# PRU_ICSS_0_INTC_local register map
Vendor: Texas Instruments
Peripheral module from a debugger description file (folder 66AK2G0x_66AK2G1x).
Registers are 32-bit, access per field, reset values left out (the file's numbers can be read two ways) unless marked. A register's access mark holds for its fields unless they carry their own. Offsets are as the file gives them; lines under a group give offsets from that group; [hi:lo] are bit positions; {n}, {i} and the like mark numbered series; 'fields as' and 'values as' point back to an identical list; <NAME> marks a mode.

## PRU_ICSS_0_INTC
0x00 PRUSS_INTC_REVID ro
  [31:0] REVISION — IP Revision
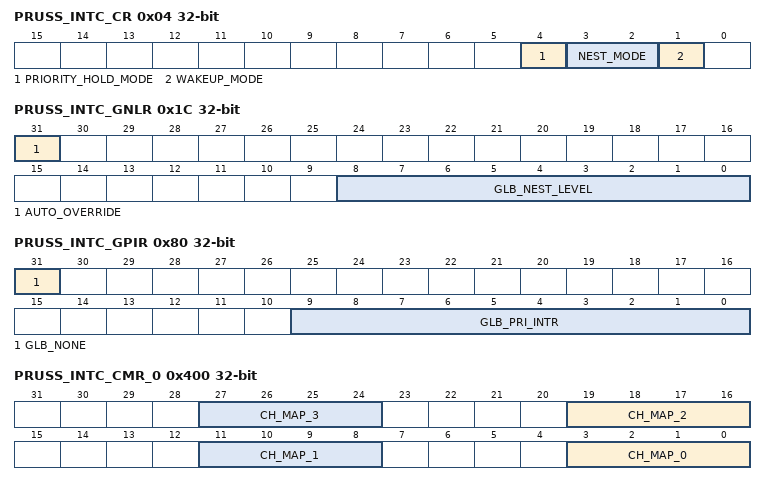
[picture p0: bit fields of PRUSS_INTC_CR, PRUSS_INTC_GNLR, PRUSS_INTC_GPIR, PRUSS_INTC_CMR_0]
0x04 PRUSS_INTC_CR
  [4] PRIORITY_HOLD_MODE rw — Reserved
  [3:2] NEST_MODE rw — The nesting mode.
  [1] WAKEUP_MODE rw — Reserved
0x10 PRUSS_INTC_GER
  [0] ENABLE_HINT_ANY rw — The current global enable value when read. Writes set the global enable.
0x1C PRUSS_INTC_GNLR
  [31] AUTO_OVERRIDE wo — Always read as 0. Writes of 1 override the automatic nesting and set the nesting_level to the written data.
  [8:0] GLB_NEST_LEVEL rw — The current global nesting level (highest channel that is nested). Writes set the nesting level. In auto nesting mode this value is updated internally unless the auto_override bit is set.
0x20 PRUSS_INTC_SISR
  [9:0] STATUS_SET_INDEX wo — Writes set the status of the interrupt given in the index value. Reads return 0.
0x24 PRUSS_INTC_SICR
  [9:0] STATUS_CLR_INDEX wo — Writes clear the status of the interrupt given in the index value. Reads return 0.
0x28 PRUSS_INTC_EISR
  [9:0] ENABLE_SET_INDEX wo — Writes set the enable of the interrupt given in the index value. Reads return 0.
0x2C PRUSS_INTC_EICR
  [9:0] ENABLE_CLR_INDEX wo — Writes clear the enable of the interrupt given in the index value. Reads return 0.
0x34 PRUSS_INTC_HIEISR
  [9:0] HINT_ENABLE_SET_INDEX rw — Writes set the enable of the host interrupt given in the index value. Reads return 0.
0x38 PRUSS_INTC_HIDISR
  [9:0] HINT_ENABLE_CLR_INDEX rw — Writes clear the enable of the host interrupt given in the index value. Reads return 0.
0x80 PRUSS_INTC_GPIR ro
  [31] GLB_NONE — No Interrupt is pending. Can be used by host to test for a negative value to see if no interrupts are pending.
  [9:0] GLB_PRI_INTR — The currently highest priority interrupt index pending across all the host interrupts.
0x200 PRUSS_INTC_SRSR0 rw
  [31:0] RAW_STATUS_31_0 — System interrupt raw status and setting of the system interrupts 0 to 31. Reads return the raw status. Write a 1 in a bit position to set the status of the system interrupt. Writing a 0 has no effect.
0x204 PRUSS_INTC_SRSR1 rw
  [31:0] RAW_STATUS_63_32 — System interrupt raw status and setting of the system interrupts 32 to 63. Reads return the raw status. Write a 1 in a bit position to set the status of the system interrupt. Writing a 0 has no effect.
0x280 PRUSS_INTC_SECR0 rw
  [31:0] ENA_STATUS_31_0 — System interrupt enabled status and clearing of the system interrupts 0 to 31. Reads return the enabled status (before enabling with the Enable Registers). Write a 1 in a bit position to clear the status of the system interrupt. Writing a 0 has no effect.
0x284 PRUSS_INTC_SECR1 rw
  [31:0] ENA_STATUS_63_32 — System interrupt enabled status and clearing of the system interrupts 32 to 63. Reads return the enabled status (before enabling with the Enable Registers). Write a 1 in a bit position to clear the status of the system interrupt. Writing a 0 has no effect.
0x300 PRUSS_INTC_ESR0 rw
  [31:0] ENABLE_SET_31_0 — System interrupt enables system interrupts 0 to 31. Read returns the enable value (0 = disabled, 1 = enabled). Write a 1 in a bit position to set that enable. Writing a 0 has no effect.
0x304 PRUSS_INTC_ERS1 rw
  [31:0] ENABLE_SET_63_32 — System interrupt enables system interrupts 32 to 63. Read returns the enable value (0 = disabled, 1 = enabled). Write a 1 in a bit position to set that enable. Writing a 0 has no effect.
0x380 PRUSS_INTC_ECR0 wo
  [31:0] ENABLE_CLR_31_0 — System interrupt enables system interrupts 0 to 31. Write a 1 in a bit position to clear that enable. Writing a 0 has no effect.
0x384 PRUSS_INTC_ECR1 wo
  [31:0] ENABLE_CLR_63_32 — System interrupt enables system interrupts 32 to 63. Write a 1 in a bit position to clear that enable. Writing a 0 has no effect.
0x400 PRUSS_INTC_CMR_0
  [8n+3:8n] CH_MAP_{n} rw (n=0..3) — Sets the channel for the system interrupt {n}
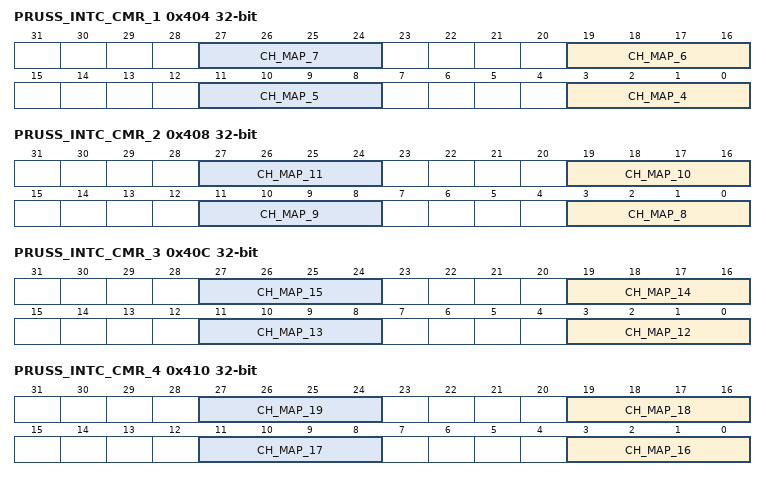
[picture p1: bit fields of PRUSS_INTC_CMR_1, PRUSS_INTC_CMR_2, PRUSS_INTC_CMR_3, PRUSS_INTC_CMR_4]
0x404 PRUSS_INTC_CMR_1
  [8n-29:8n-32] CH_MAP_{n} rw (n=4..7) — Sets the channel for the system interrupt {n}
0x408 PRUSS_INTC_CMR_2
  [8n-61:8n-64] CH_MAP_{n} rw (n=8..11) — Sets the channel for the system interrupt {n}
0x40C PRUSS_INTC_CMR_3
  [8n-93:8n-96] CH_MAP_{n} rw (n=12..15) — Sets the channel for the system interrupt {n}
0x410 PRUSS_INTC_CMR_4
  [8n-125:8n-128] CH_MAP_{n} rw (n=16..19) — Sets the channel for the system interrupt {n}
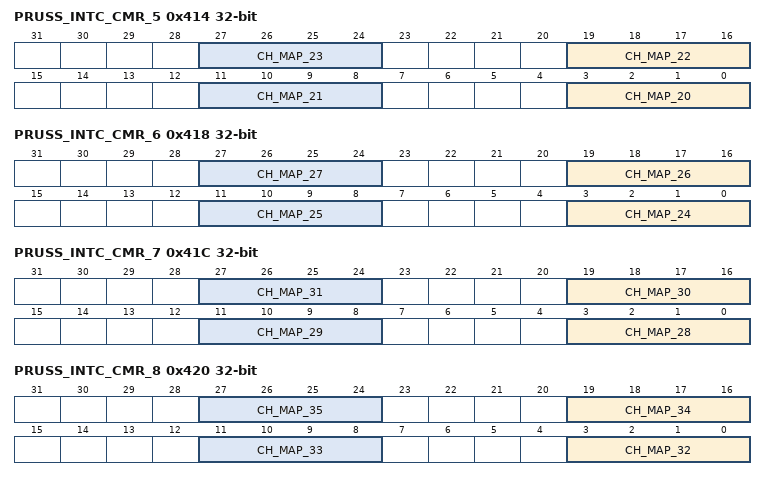
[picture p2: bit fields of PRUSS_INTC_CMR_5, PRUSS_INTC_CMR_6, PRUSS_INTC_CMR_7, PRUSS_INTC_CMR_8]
0x414 PRUSS_INTC_CMR_5
  [8n-157:8n-160] CH_MAP_{n} rw (n=20..23) — Sets the channel for the system interrupt {n}
0x418 PRUSS_INTC_CMR_6
  [8n-189:8n-192] CH_MAP_{n} rw (n=24..27) — Sets the channel for the system interrupt {n}
0x41C PRUSS_INTC_CMR_7
  [8n-221:8n-224] CH_MAP_{n} rw (n=28..31) — Sets the channel for the system interrupt {n}
0x420 PRUSS_INTC_CMR_8
  [8n-253:8n-256] CH_MAP_{n} rw (n=32..35) — Sets the channel for the system interrupt {n}
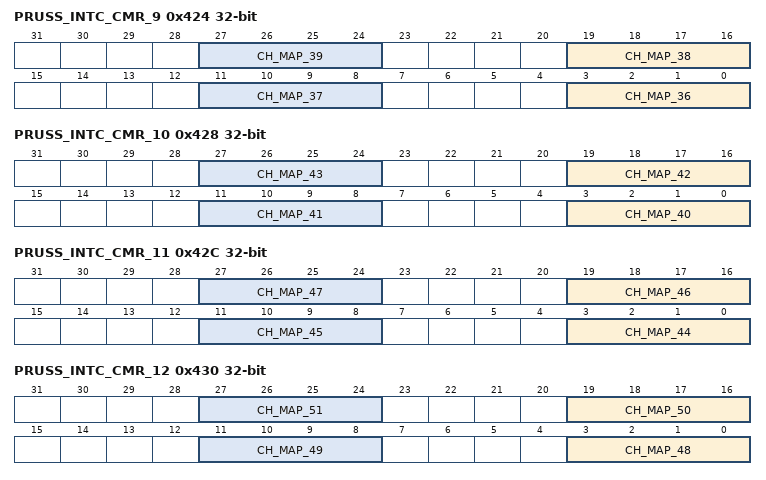
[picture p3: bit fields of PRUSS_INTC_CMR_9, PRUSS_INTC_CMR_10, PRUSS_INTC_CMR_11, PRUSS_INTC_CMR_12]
0x424 PRUSS_INTC_CMR_9
  [8n-285:8n-288] CH_MAP_{n} rw (n=36..39) — Sets the channel for the system interrupt {n}
0x428 PRUSS_INTC_CMR_10
  [8n-317:8n-320] CH_MAP_{n} rw (n=40..43) — Sets the channel for the system interrupt {n}
0x42C PRUSS_INTC_CMR_11
  [8n-349:8n-352] CH_MAP_{n} rw (n=44..47) — Sets the channel for the system interrupt {n}
0x430 PRUSS_INTC_CMR_12
  [8n-381:8n-384] CH_MAP_{n} rw (n=48..51) — Sets the channel for the system interrupt {n}
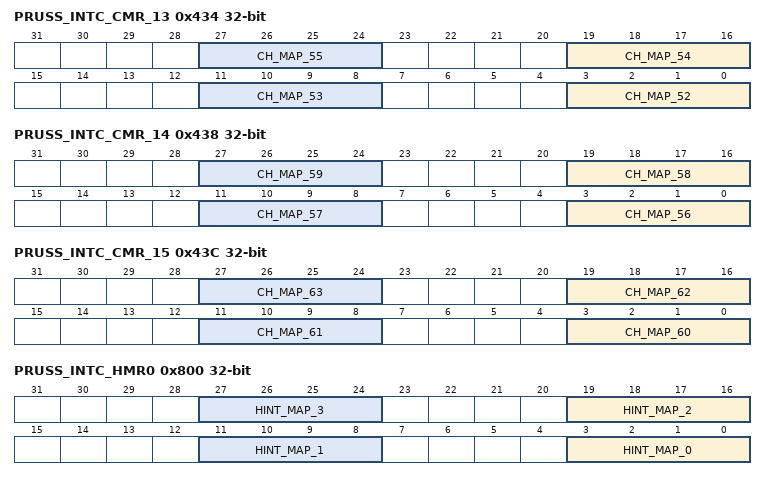
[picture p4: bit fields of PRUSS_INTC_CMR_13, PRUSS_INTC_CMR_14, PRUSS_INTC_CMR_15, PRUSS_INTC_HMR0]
0x434 PRUSS_INTC_CMR_13
  [8n-413:8n-416] CH_MAP_{n} rw (n=52..55) — Sets the channel for the system interrupt {n}
0x438 PRUSS_INTC_CMR_14
  [8n-445:8n-448] CH_MAP_{n} rw (n=56..59) — Sets the channel for the system interrupt {n}
0x43C PRUSS_INTC_CMR_15
  [8n-477:8n-480] CH_MAP_{n} rw (n=60..63) — Sets the channel for the system interrupt {n}
0x800 PRUSS_INTC_HMR0
  [8n+3:8n] HINT_MAP_{n} rw (n=0..3) — HOST INTERRUPT MAP FOR CHANNEL {n}
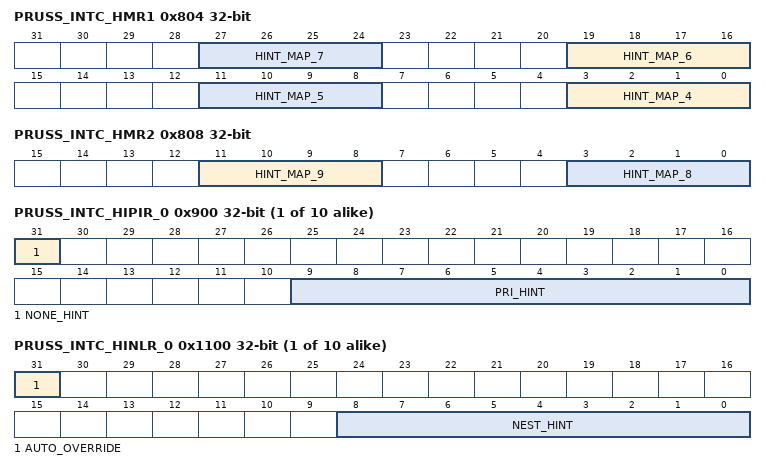
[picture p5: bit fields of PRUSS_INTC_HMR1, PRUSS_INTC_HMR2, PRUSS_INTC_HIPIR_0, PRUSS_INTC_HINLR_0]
0x804 PRUSS_INTC_HMR1
  [8n-29:8n-32] HINT_MAP_{n} rw (n=4..7) — HOST INTERRUPT MAP FOR CHANNEL {n}
0x808 PRUSS_INTC_HMR2
  [11:8] HINT_MAP_9 rw — HOST INTERRUPT MAP FOR CHANNEL 9
  [3:0] HINT_MAP_8 rw — HOST INTERRUPT MAP FOR CHANNEL 8
{0x900+4i} PRUSS_INTC_HIPIR_{i} ro (i=0..9)
  [31] NONE_HINT — No pending interrupt.
  [9:0] PRI_HINT — HOST INT j PRIORITIZED INTERRUPT. Interrupt number of the highest priority pending interrupt for this host interrupt.
0xD00 PRUSS_INTC_SIPR0 rw
  [31:0] POLARITY_31_0 — Interrupt polarity of the system interrupts 0 to 31.
0xD04 PRUSS_INTC_SIPR1 rw
  [31:0] POLARITY_63_32 — Interrupt polarity of the system interrupts 32 to 63.
0xD80 PRUSS_INTC_SITR0 rw
  [31:0] TYPE_31_0 — Interrupt type of the system interrupts 0 to 31.
0xD84 PRUSS_INTC_SITR1 rw
  [31:0] TYPE_63_32 — Interrupt type of the system interrupts 32 to 63.
{0x1100+4i} PRUSS_INTC_HINLR_{i} (i=0..9)
  [31] AUTO_OVERRIDE wo — Reads return 0. Writes of a 1 override the auto updating of the nesting_level and use the write data.
  [8:0] NEST_HINT rw — Reads return the current nesting level for the host interrupt. Writes set the nesting level for the host interrupt. In auto mode the value is updated internally unless the auto_override is set and then the write data is used.
0x1500 PRUSS_INTC_HIER
  [9:0] ENABLE_HINT rw — The enable of the host interrupts (one per bit).
